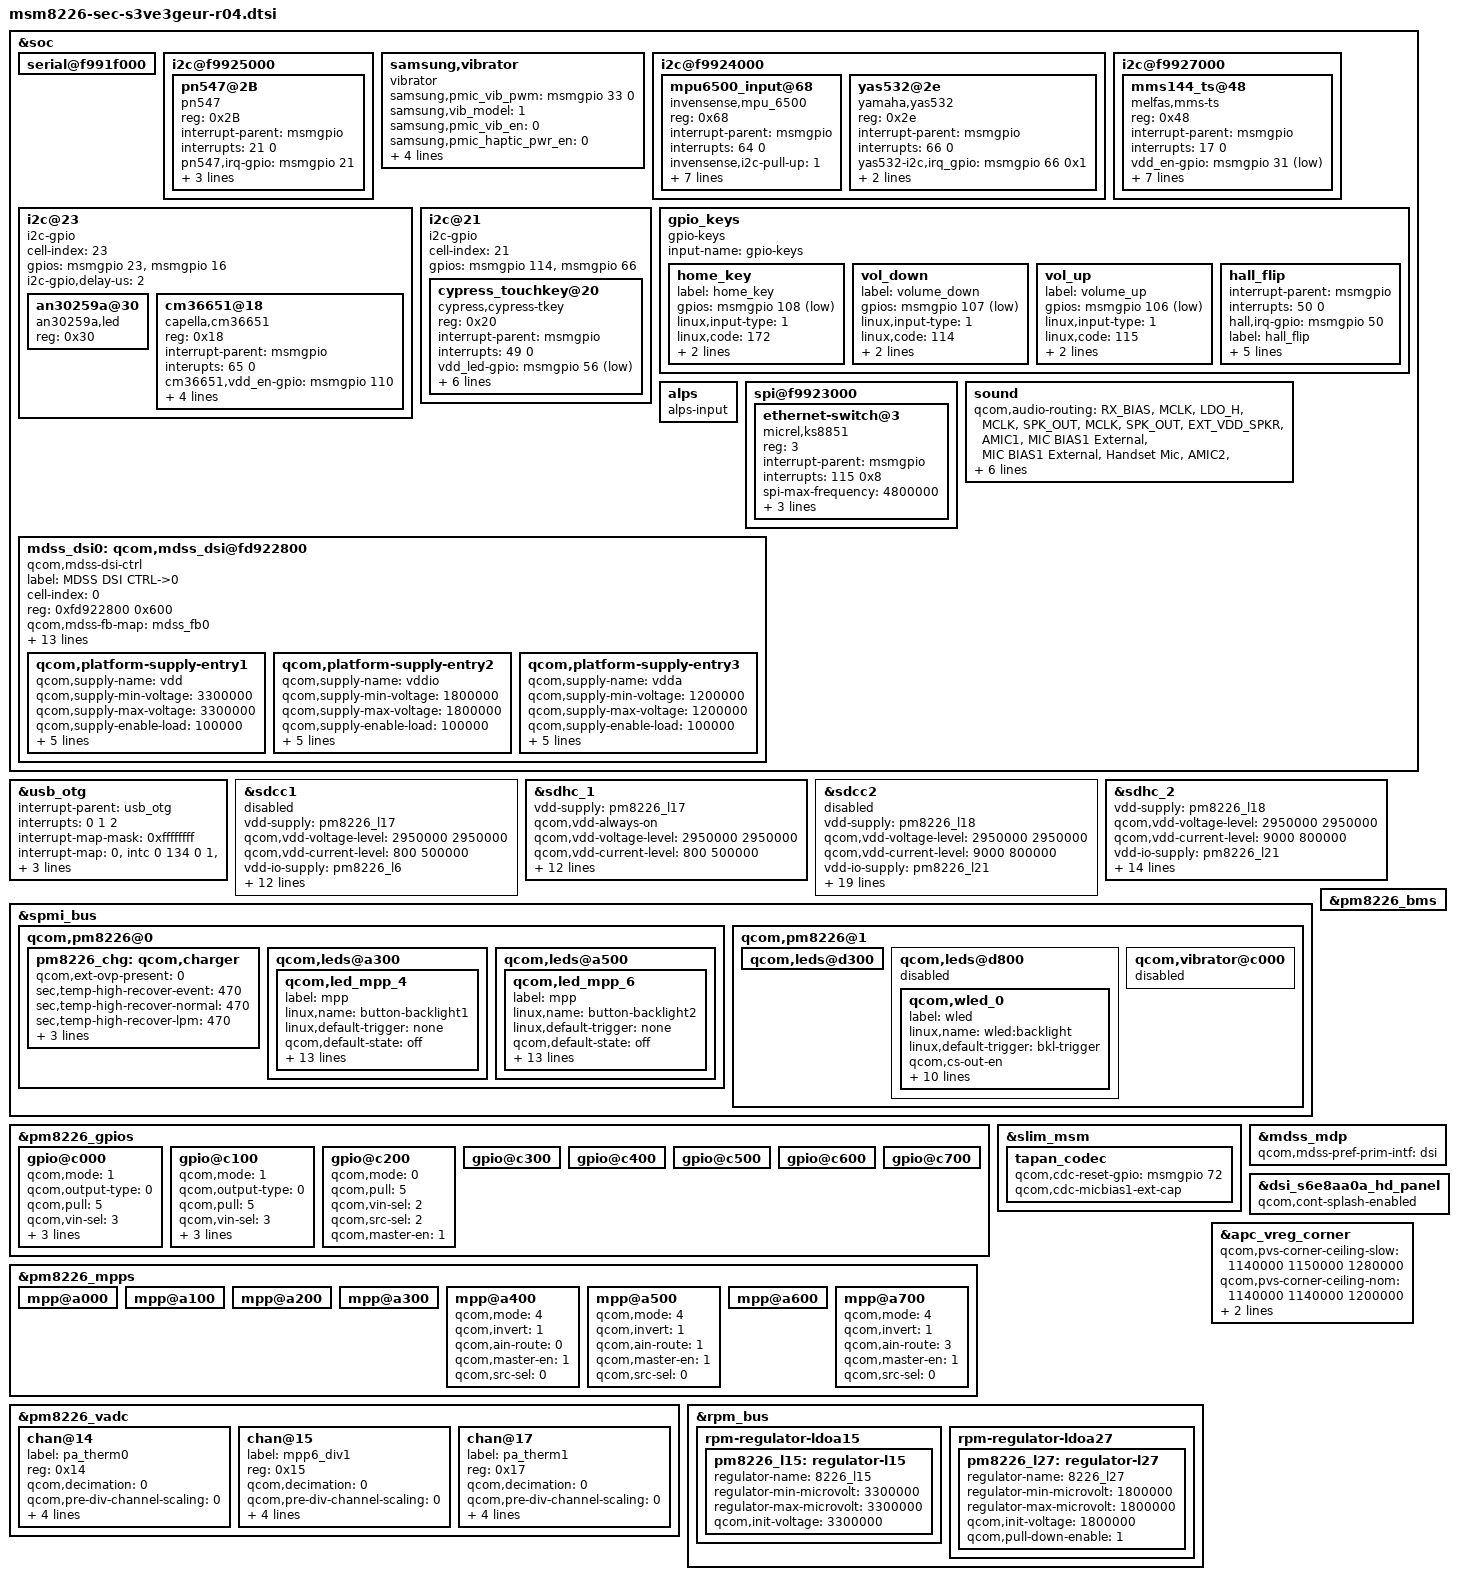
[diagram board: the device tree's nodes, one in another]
/* Copyright (c) 2013, The Linux Foundation. All rights reserved.
 *
 * This program is free software; you can redistribute it and/or modify
 * it under the terms of the GNU General Public License version 2 and
 * only version 2 as published by the Free Software Foundation.
 *
 * This program is distributed in the hope that it will be useful,
 * but WITHOUT ANY WARRANTY; without even the implied warranty of
 * MERCHANTABILITY or FITNESS FOR A PARTICULAR PURPOSE.  See the
 * GNU General Public License for more details.
 */

/include/ "dsi-panel-s6e8aa0a-720p-video.dtsi"
/include/ "msm8226-camera-sensor-mtp-s3ve-r01.dtsi"
/include/ "msm8226-sm5502.dtsi"
/*/include/ "msm8226-s3ve-sensor-r01.dtsi"*/

&soc {
	serial@f991f000 {
		status = "ok";
	};

	i2c@f9925000 {
		pn547@2B {
			compatible = "pn547";
			reg = <0x2B>;
			interrupt-parent = <&msmgpio>;
			interrupts = <21 0>;
			pn547,irq-gpio = <&msmgpio 21 0x00>;
			pn547,ven-gpio = <&msmgpio 20 0x1>;
			pn547,firm-gpio = <&msmgpio 62 0x00>;
			pn547,clk_req_gpio = <&pm8226_gpios 3 0x0>;
		};
	};

	samsung,vibrator {
			compatible = "vibrator";
			samsung,pmic_vib_pwm = <&msmgpio 33 0>;
			samsung,vib_model = <1>;
			samsung,pmic_vib_en = <0>;
			samsung,pmic_haptic_pwr_en = <0>;
			samsung,is_pmic_vib_pwm = <0>;
			samsung,pwm_period_us = <40>;
			samsung,duty_us = <36>;
			samsung,drv2603_en = <&msmgpio 111 0>;
			status = "ok";
	};

	i2c@f9924000 { /* BLSP1 QUP2 */
		mpu6500_input@68 {
			compatible = "invensense,mpu_6500";
			reg = <0x68>;
			interrupt-parent = <&msmgpio>;
			interrupts = <64 0>;
			invensense,i2c-pull-up = <1>;
			invensense-i2c,reg_vdd = "8226_l19";
			invensense-i2c,reg_vio = "8226_lvs1";
	             	invensense,irq-gpio= <&msmgpio 64 0x1>;
			invensense,scl-gpio = <&msmgpio 7 0x00>;
			invensense,sda-gpio = <&msmgpio 6 0x00>;
			invensense,acc_cal_path = "/efs/calibration_data";
			invensense,gyro_cal_path = "/efs/gyro_cal_data";
		};
		yas532@2e {
			compatible = "yamaha,yas532";
			reg = <0x2e>;
			interrupt-parent = <&msmgpio>;
			interrupts = <66 0>;
			yas532-i2c,irq_gpio = <&msmgpio 66 0x1>;
			yas532-i2c,reg_vdd = "8226_l19";
			yas532-i2c,reg_vio = "8226_lvs1";
		};
	};

	i2c@f9927000 { /* BLSP1 QUP5 */
//		compatible = "qcom,i2c-qup";
//		qcom,scl-gpio = <&msmgpio 19 0>;
//		qcom,sda-gpio = <&msmgpio 18 0>;

//		qcom,i2c-bus-freq = <400000>;

		mms144_ts@48 {
			compatible = "melfas,mms-ts";
			reg = <0x48>;
				interrupt-parent = <&msmgpio>;
				interrupts = <17 0>;
			vdd_en-gpio = <&msmgpio 31 0x01>;
			vcc_i2c-supply = <&pm8226_lvs1>;
			melfas,scl-gpio = <&msmgpio 19 0x00>;
			melfas,sda-gpio = <&msmgpio 18 0x00>;
			melfas,irq-gpio = <&msmgpio 17 0x00>;
			melfas,panel-coords = <0  0 720 1280>;
			melfas,config_fw_version = "melfas mms144";
			melfas,i2c-pull-up = <1>;
		};
	};

	i2c@23 {
		cell-index = <23>;
		compatible = "i2c-gpio";
		gpios = <&msmgpio 23 0 /* sda */
		&msmgpio 16 0 /* scl */
		>;
                i2c-gpio,delay-us = <2>;
		an30259a@30 {
			compatible = "an30259a,led";
			reg = <0x30>;
		};
              cm36651@18{
                    compatible = "capella,cm36651";
                    reg = <0x18>;
                    interrupt-parent = <&msmgpio>;
                    interupts= <65 0>;
		      cm36651,vdd_en-gpio = <&msmgpio 110 0>;
		      cm36651,p_out-gpio = <&msmgpio 65 0>;
		      cm36651,prox_cal_path = "/efs/prox_cal";
		      cm36651,vdd_2p85 = "8226_l19";
		      cm36651,version = <1>;
            };

	};

	i2c@21 { 
		cell-index = <21>;
		compatible = "i2c-gpio";
		gpios = <&msmgpio 114 0 /* sda */
		&msmgpio 66 0 /* scl */
		>;
	
		cypress_touchkey@20 {
			compatible = "cypress,cypress-tkey";
			reg = <0x20>;
			interrupt-parent = <&msmgpio>;
			interrupts = <49 0>;
			vdd_led-gpio = <&msmgpio 56 0x1>;
//			vcc_en-supply = <&pm8226_lvs1>;
			vdd_en-gpio = <&msmgpio 67 0x01>;
			cypress,scl-gpio = <&msmgpio 66 0x00>;
			cypress,sda-gpio = <&msmgpio 114 0x00>;
			cypress,irq-gpio = <&msmgpio 49 0x1>;
			cypress,tkey-keycodes = <158 139>;
			cypress,i2c-pull-up = <1>;
		};
	};

	gpio_keys {
		compatible = "gpio-keys";
		input-name = "gpio-keys";

		home_key {
			label = "home_key";
			gpios = <&msmgpio 108 0x1>;
			linux,input-type = <1>;
			linux,code = <172>;
			gpio-key,wakeup;
			debounce-interval = <15>;
		};

		vol_down {
			label = "volume_down";
			gpios = <&msmgpio 107 0x1>;
			linux,input-type = <1>;
			linux,code = <114>;
			gpio-key,wakeup;
			debounce-interval = <15>;
		};

		vol_up {
			label = "volume_up";
			gpios = <&msmgpio 106 0x1>;
			linux,input-type = <1>;
			linux,code = <115>;
			gpio-key,wakeup;
			debounce-interval = <15>;
		};

		hall_flip {
			interrupt-parent = <&msmgpio>;
			interrupts = <50 0>;
			hall,irq-gpio = <&msmgpio 50 0x00>;

			label = "hall_flip";
			gpios = <&msmgpio 50 0>;
			linux,input-type = <1>;
			linux,code = <0x15>;
			gpio-key,wakeup;
			debounce-interval = <15>;
		};
	};
	alps {
			compatible = "alps-input";
	};
	spi@f9923000 {
		ethernet-switch@3 {
			compatible = "micrel,ks8851";
			reg = <3>;
			interrupt-parent = <&msmgpio>;
			interrupts = <115 0x8>;
			spi-max-frequency = <4800000>;
			rst-gpio = <&msmgpio 114 0>;
			vdd-io-supply = <&pm8226_lvs1>;
			vdd-phy-supply = <&pm8226_lvs1>;
		};
	};

	sound {
		qcom,audio-routing =
			"RX_BIAS", "MCLK",
			"LDO_H", "MCLK",
			"SPK_OUT", "MCLK",
			"SPK_OUT", "EXT_VDD_SPKR",
			"AMIC1", "MIC BIAS1 External",
			"MIC BIAS1 External", "Handset Mic",
			"AMIC2", "MIC BIAS2 External",
			"MIC BIAS2 External", "Headset Mic",
			"AMIC3", "MIC BIAS1 External",
			"MIC BIAS1 External", "ANCRight Headset Mic",
			"AMIC4", "MIC BIAS2 External",
			"MIC BIAS2 External", "ANCLeft Headset Mic";

		qcom,cdc-mclk-gpios = <&pm8226_gpios 1 0>;
		/*qcom,cdc-vdd-spkr-gpios = <&pm8226_gpios 2 0>;*/
	};

	mdss_dsi0: qcom,mdss_dsi@fd922800 {
		compatible = "qcom,mdss-dsi-ctrl";
		label = "MDSS DSI CTRL->0";
		cell-index = <0>;
		reg = <0xfd922800 0x600>;
		qcom,mdss-fb-map = <&mdss_fb0>;
		vdd-supply = <&pm8226_l15>;
		vddio-supply = <&pm8226_l8>;
		vdda-supply = <&pm8226_l4>;
		qcom,disp-on-gpio = <&msmgpio 73 0>;
		qcom,platform-reset-gpio = <&msmgpio 25 1>;
		qcom,platform-strength-ctrl = [ff 06];
		qcom,platform-bist-ctrl = [00 00 b1 ff 00 00];
		qcom,platform-regulator-settings = [03 01 01 00 20 00 01];
		qcom,platform-lane-config = [00 00 00 00 00 00 00 01 75
						 00 00 00 00 05 00 00 01 75
						 00 00 00 00 0a 00 00 01 75
						 00 00 00 00 0f 00 00 01 75
						 00 c0 00 00 00 00 00 01 97];
		qcom,platform-reset-sequence = <1 20 0 20 1 20>;
		qcom,platform-supply-entry1 {
			qcom,supply-name = "vdd";
			qcom,supply-min-voltage = <3300000>;
			qcom,supply-max-voltage = <3300000>;
			qcom,supply-enable-load = <100000>;
			qcom,supply-disable-load = <100>;
			qcom,supply-pre-on-sleep = <0>;
			qcom,supply-post-on-sleep = <0>;
			qcom,supply-pre-off-sleep = <0>;
			qcom,supply-post-off-sleep = <0>;
		};
		qcom,platform-supply-entry2 {
			qcom,supply-name = "vddio";
			qcom,supply-min-voltage = <1800000>;
			qcom,supply-max-voltage = <1800000>;
			qcom,supply-enable-load = <100000>;
			qcom,supply-disable-load = <100>;
			qcom,supply-pre-on-sleep = <0>;
			qcom,supply-post-on-sleep = <0>;
			qcom,supply-pre-off-sleep = <0>;
			qcom,supply-post-off-sleep = <0>;
		};
		qcom,platform-supply-entry3 {
			qcom,supply-name = "vdda";
			qcom,supply-min-voltage = <1200000>;
			qcom,supply-max-voltage = <1200000>;
			qcom,supply-enable-load = <100000>;
			qcom,supply-disable-load = <100>;
			qcom,supply-pre-on-sleep = <0>;
			qcom,supply-post-on-sleep = <20>;
			qcom,supply-pre-off-sleep = <0>;
			qcom,supply-post-off-sleep = <0>;
		};
	};
};

&usb_otg {
	#address-cells = <0>;
	interrupt-parent = <&usb_otg>;
	interrupts = <0 1 2>;
	#interrupt-cells = <1>;
	interrupt-map-mask = <0xffffffff>;
	interrupt-map = <0 &intc 0 134 0
			1 &intc 0 140 0
			2 &spmi_bus 0x0 0x0 0x9 0x0>;
	interrupt-names = "core_irq", "async_irq", "pmic_id_irq";

	qcom,hsusb-otg-mode = <3>;
	vbus_otg-supply = <&pm8226_chg_otg>;
};

&sdcc1 {
	vdd-supply = <&pm8226_l17>;
	qcom,vdd-voltage-level = <2950000 2950000>;
	qcom,vdd-current-level = <800 500000>;

	vdd-io-supply = <&pm8226_l6>;
	qcom,vdd-io-always-on;
	qcom,vdd-io-voltage-level = <1800000 1800000>;
	qcom,vdd-io-current-level = <250 154000>;

	qcom,pad-pull-on = <0x0 0x3 0x3>; /* no-pull, pull-up, pull-up */
	qcom,pad-pull-off = <0x0 0x3 0x3>; /* no-pull, pull-up, pull-up */
	qcom,pad-drv-on = <0x4 0x4 0x4>; /* 10mA, 10mA, 10mA */
	qcom,pad-drv-off = <0x0 0x0 0x0>; /* 2mA, 2mA, 2mA */

	qcom,clk-rates = <400000 25000000 50000000 100000000 200000000>;
	qcom,sup-voltages = <2950 2950>;

	qcom,bus-speed-mode = "HS200_1p8v", "DDR_1p8v";
	qcom,nonremovable;

	status = "disabled";
};

&sdhc_1 {
	vdd-supply = <&pm8226_l17>;
	qcom,vdd-always-on;
	qcom,vdd-voltage-level = <2950000 2950000>;
	qcom,vdd-current-level = <800 500000>;

	vdd-io-supply = <&pm8226_l6>;
	qcom,vdd-io-always-on;
	qcom,vdd-io-voltage-level = <1800000 1800000>;
	qcom,vdd-io-current-level = <250 154000>;

	qcom,pad-pull-on = <0x0 0x3 0x3>; /* no-pull, pull-up, pull-up */
	qcom,pad-pull-off = <0x0 0x3 0x3>; /* no-pull, pull-up, pull-up */
	qcom,pad-drv-on = <0x4 0x4 0x4>; /* 10mA, 10mA, 10mA */
	qcom,pad-drv-off = <0x0 0x0 0x0>; /* 2mA, 2mA, 2mA */

	qcom,clk-rates = <400000 25000000 50000000 100000000 200000000>;
	qcom,bus-speed-mode = "HS200_1p8v", "DDR_1p8v";
	qcom,nonremovable;

	status = "ok";
};

&sdcc2 {
	vdd-supply = <&pm8226_l18>;
	qcom,vdd-voltage-level = <2950000 2950000>;
	qcom,vdd-current-level = <9000 800000>;

	vdd-io-supply = <&pm8226_l21>;
	qcom,vdd-io-voltage-level = <1800000 2950000>;
	qcom,vdd-io-current-level = <6 22000>;

	qcom,pad-pull-on = <0x0 0x3 0x3>; /* no-pull, pull-up, pull-up */
	qcom,pad-pull-off = <0x0 0x3 0x3>; /* no-pull, pull-up, pull-up */
	qcom,pad-drv-on = <0x4 0x4 0x4>; /* 10mA, 10mA, 10mA */
	qcom,pad-drv-off = <0x0 0x0 0x0>; /* 2mA, 2mA, 2mA */

	qcom,clk-rates = <400000 25000000 50000000 100000000 200000000>;
	qcom,sup-voltages = <2950 2950>;

	qcom,xpc;
	qcom,bus-speed-mode = "SDR12", "SDR25", "SDR50", "DDR50", "SDR104";
	qcom,current-limit = <600>; #address-cells = <0>; interrupt-parent = <&sdcc2>;
	interrupts = <0 1 2>;
	#interrupt-cells = <1>;
	interrupt-map-mask = <0xffffffff>;
	interrupt-map = <0 &intc 0 125 0
			1 &intc 0 220 0
			2 &msmgpio 38 0x3>;
	interrupt-names = "core_irq", "bam_irq", "status_irq";
	cd-gpios = <&msmgpio 38 0x1>;

	status = "disabled";
};

&sdhc_2 {
	vdd-supply = <&pm8226_l18>;
	qcom,vdd-voltage-level = <2950000 2950000>;
	qcom,vdd-current-level = <9000 800000>;

	vdd-io-supply = <&pm8226_l21>;
	qcom,vdd-io-voltage-level = <1800000 2950000>;
	qcom,vdd-io-current-level = <6 22000>;

	qcom,pad-pull-on = <0x0 0x3 0x3>; /* no-pull, pull-up, pull-up */
	qcom,pad-pull-off = <0x0 0x1 0x1>; /* no-pull, pull-down, pull-down */
	qcom,pad-drv-on = <0x4 0x4 0x4>; /* 10mA, 10mA, 10mA */
	qcom,pad-drv-off = <0x0 0x0 0x0>; /* 2mA, 2mA, 2mA */

	qcom,clk-rates = <400000 25000000 50000000 100000000 200000000>;

	#address-cells = <0>;
	interrupt-parent = <&sdhc_2>;
	interrupts = <0 1 2>;
	#interrupt-cells = <1>;
	interrupt-map-mask = <0xffffffff>;
	interrupt-map = <0 &intc 0 125 0
			1 &intc 0 221 0
			2 &msmgpio 38 0x3>;
	interrupt-names = "hc_irq", "pwr_irq", "status_irq";
	cd-gpios = <&msmgpio 38 0x1>;

	status = "ok";
};

&spmi_bus {
	qcom,pm8226@0 {
		pm8226_chg: qcom,charger {
			qcom,ext-ovp-present = <0>;
			sec,temp-high-recover-event = <470>;
			sec,temp-high-recover-normal = <470>;
			sec,temp-high-recover-lpm = <470>;
		};
		
		qcom,leds@a300 {
			status = "okay";
			qcom,led_mpp_4 {
				label = "mpp";
				linux,name = "button-backlight1";
				linux,default-trigger = "none";
				qcom,default-state = "off";
				qcom,max-current = <40>;
				qcom,current-setting = <5>;
				qcom,id = <6>;
				qcom,mode = "pwm";
				qcom,pwm-us = <1000>;
				qcom,source-sel = <8>;
				qcom,mode-ctrl = <0x60>;
				qcom,pwm-channel = <0>;
				qcom,start-idx = <1>;
				qcom,ramp-step-ms = <120>;
				qcom,duty-pcts = [00 00 00 00 00
						  00 00 00 00 00
						  50 00 00 00 00
						  00 00 00 00 00
						  00];
				qcom,use-blink;
			};
		};

		qcom,leds@a500 {
			status = "okay";
			qcom,led_mpp_6 {
				label = "mpp";
				linux,name = "button-backlight2";
				linux,default-trigger = "none";
				qcom,default-state = "off";
				qcom,max-current = <40>;
				qcom,current-setting = <5>;
				qcom,id = <6>;
				qcom,mode = "pwm";
				qcom,pwm-us = <1000>;
				qcom,mode-ctrl = <0x60>;
				qcom,source-sel = <10>;
				qcom,pwm-channel = <5>;
				qcom,start-idx = <1>;
				qcom,ramp-step-ms = <120>;
				qcom,duty-pcts = [00 00 00 00 00
						  00 00 00 00 00
						  50 00 00 00 00
						  00 00 00 00 00
						  00];
				qcom,use-blink;
			};
		};
	};

	qcom,pm8226@1 {
                qcom,leds@d300 {
                        status = "okay";
                };

		qcom,leds@d800 {
			status = "disabled"; /*If WLED is not used for Backlight control*/
			qcom,wled_0 {		/*for TFT Panel, this to be disabled */
				label = "wled";
				linux,name = "wled:backlight";
				linux,default-trigger = "bkl-trigger";
				qcom,cs-out-en;
				qcom,op-fdbck = <1>;
				qcom,default-state = "off";
				qcom,max-current = <20>;
				qcom,ctrl-delay-us = <0>;
				qcom,boost-curr-lim = <3>;
				qcom,cp-sel = <0>;
				qcom,switch-freq = <11>;
				qcom,ovp-val = <0>;
				qcom,num-strings = <1>;
				qcom,id = <0>;
			};
		};
		qcom,vibrator@c000 {
				status = "disabled";
		};
	};
};

&pm8226_gpios {
	gpio@c000 { /* GPIO 1 */
		/* XO_PMIC_CDC_MCLK enable for tapan codec */
		qcom,mode = <1>;		/* Digital output */
		qcom,output-type = <0>;	/* CMOS logic */
		qcom,pull = <5>;		/* QPNP_PIN_PULL_NO*/
		qcom,vin-sel = <3>;		/* QPNP_PIN_VIN3 */
		qcom,out-strength = <3>;/* QPNP_PIN_OUT_STRENGTH_HIGH */
		qcom,src-sel = <2>;		/* QPNP_PIN_SEL_FUNC_1 */
		qcom,master-en = <1>;	/* Enable GPIO */
	};

	gpio@c100 { /* GPIO 2 */
		qcom,mode = <1>;
		qcom,output-type = <0>;
		qcom,pull = <5>;
		qcom,vin-sel = <3>;
		qcom,out-strength = <3>;
		qcom,src-sel = <2>;
		qcom,master-en = <1>;
	};

	gpio@c200 { /* GPIO 3 */
		qcom,mode = <0>;		/* QPNP_PIN_MODE_DIG_IN */
		qcom,pull = <5>;		/* QPNP_PIN_PULL_NO */
		qcom,vin-sel = <2>;		/* QPNP_PIN_VIN2 */
		qcom,src-sel = <2>;		/* QPNP_PIN_SEL_FUNC_1 */
		qcom,master-en = <1>;
	};

	gpio@c300 { /* GPIO 4 */
	};

	gpio@c400 { /* GPIO 5 */
	};

	gpio@c500 { /* GPIO 6 */
	};

	gpio@c600 { /* GPIO 7 */
	};

	gpio@c700 { /* GPIO 8 */
	};
};

&pm8226_mpps {
	mpp@a000 { /* MPP 1 */
	};

	mpp@a100 { /* MPP 2 */
	};

	mpp@a200 { /* MPP 3 */
	};

	mpp@a300 { /* MPP 4 */
	};

	mpp@a400 { /* MPP 5 */
		/* PA_THERM0 config */
		qcom,mode = <4>; /* AIN input */
		qcom,invert = <1>; /* Enable MPP */
		qcom,ain-route = <0>; /* AMUX 5 */
		qcom,master-en = <1>;
		qcom,src-sel = <0>; /* Function constant */
	};

	mpp@a500 { /* MPP 6 */
		qcom,mode = <4>; /* AIN input */
		qcom,invert = <1>; /* Enable MPP */
		qcom,ain-route = <1>; /* AMUX 6 */
		qcom,master-en = <1>;
		qcom,src-sel = <0>; /* Function constant */
	};

	mpp@a600 { /* MPP 7 */
	};

	mpp@a700 { /* MPP 8 */
		/* PA_THERM1 config */
		qcom,mode = <4>; /* AIN input */
		qcom,invert = <1>; /* Enable MPP */
		qcom,ain-route = <3>; /* AMUX 8 */
		qcom,master-en = <1>;
		qcom,src-sel = <0>; /* Function constant */
	};
};

&pm8226_vadc {
	chan@14 {
		label = "pa_therm0";
		reg = <0x14>;
		qcom,decimation = <0>;
		qcom,pre-div-channel-scaling = <0>;
		qcom,calibration-type = "ratiometric";
		qcom,scale-function = <2>;
		qcom,hw-settle-time = <2>;
		qcom,fast-avg-setup = <0>;
	};
	chan@15 {
		label = "mpp6_div1";
		reg = <0x15>;
		qcom,decimation = <0>;
		qcom,pre-div-channel-scaling = <0>;
		qcom,calibration-type = "absolute";
		qcom,scale-function = <0>;
		qcom,hw-settle-time = <0>;
		qcom,fast-avg-setup = <0>;
	};

	chan@17 {
		label = "pa_therm1";
		reg = <0x17>;
		qcom,decimation = <0>;
		qcom,pre-div-channel-scaling = <0>;
		qcom,calibration-type = "ratiometric";
		qcom,scale-function = <2>;
		qcom,hw-settle-time = <2>;
		qcom,fast-avg-setup = <0>;
	};
};

&pm8226_bms {
	status = "ok";
};

&pm8226_chg {
	qcom,charging-disabled;
	sec,imax-ta = <1000>;
	sec,imax-usb = <500>;
};

&slim_msm {
	tapan_codec {
		qcom,cdc-reset-gpio = <&msmgpio 72 0>;
		qcom,cdc-micbias1-ext-cap;
	};
};

&rpm_bus {
	rpm-regulator-ldoa15 {
		status = "okay";
		pm8226_l15: regulator-l15 {
			regulator-name = "8226_l15";
			regulator-min-microvolt = <3300000>;
			regulator-max-microvolt = <3300000>;
			qcom,init-voltage = <3300000>;
			status = "okay";
		};
	};

	rpm-regulator-ldoa27 {
		status = "okay";
		pm8226_l27: regulator-l27 {
			regulator-name = "8226_l27";
			regulator-min-microvolt = <1800000>;
			regulator-max-microvolt = <1800000>;
			qcom,init-voltage = <1800000>;
			qcom,pull-down-enable = <1>;
			status = "okay";
		};
	};
};

&mdss_mdp {
	qcom,mdss-pref-prim-intf = "dsi";
};

&mdss_dsi0 {
	qcom,dsi-pref-prim-pan = <&dsi_s6e8aa0a_hd_panel>;
};

&dsi_s6e8aa0a_hd_panel {
	qcom,cont-splash-enabled;
};

&apc_vreg_corner {
	qcom,pvs-corner-ceiling-slow = <1140000 1150000 1280000>;
	qcom,pvs-corner-ceiling-nom  = <1140000 1140000 1200000>;
	qcom,pvs-corner-ceiling-fast = <1140000 1140000 1140000>;
};

